AUTOSAR XML (schema 4-2-2)
package /Acme/Chassis/Types
  base type Octet: category=FIXED_LENGTH, base-type-size=8, base-type-encoding=NONE, native-declaration=uint8
  impl type Level: category=VALUE, base-type=Octet
package /Acme/Chassis/Interfaces
  sender receiver interface ILevel
    data level: type=Level
package /Acme/Chassis/Components
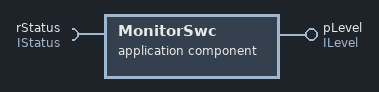
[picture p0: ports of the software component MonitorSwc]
  application sw component type MonitorSwc
    provide port pLevel: provided-interface=ILevel
    require port rStatus: required-interface=IStatus
